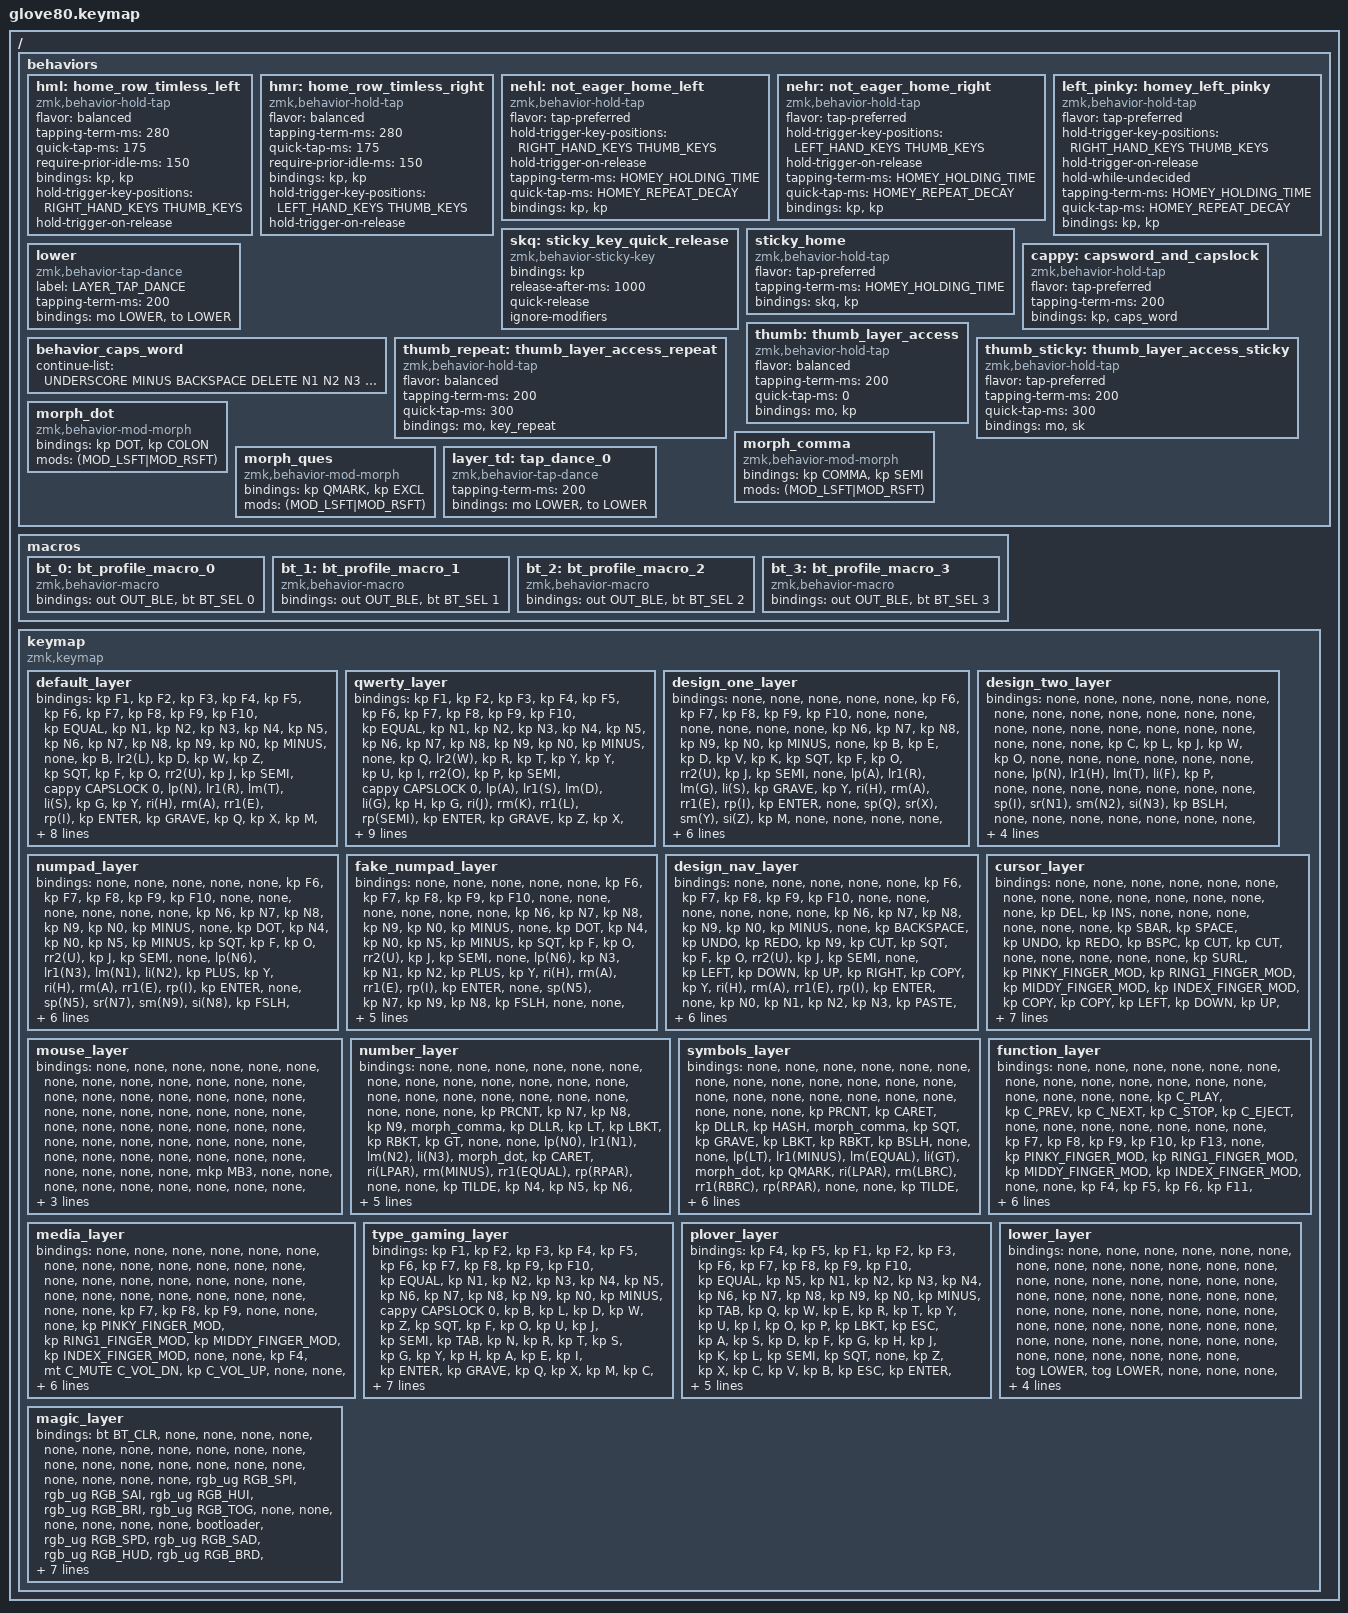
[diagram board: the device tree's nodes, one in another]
/*
 * Copyright (c) 2020 The ZMK Contributors
 *
 * SPDX-License-Identifier: MIT
 */


#include <dt-bindings/zmk/hid_usage.h>
#include <dt-bindings/zmk/hid_usage_pages.h>
#include <dt-bindings/zmk/modifiers.h>

#include <dt-bindings/zmk/mouse.h>
#include <dt-bindings/zmk/keys.h>
#include <dt-bindings/zmk/bt.h>
#include <dt-bindings/zmk/ext_power.h>
#include <dt-bindings/zmk/outputs.h>
#include <dt-bindings/zmk/rgb.h>

#include <behaviors.dtsi>
 
#include "./config.dtsi"
#include "./features/thumbs.dtsi"
#include "./features/shortcuts.dtsi"
#include "./features/combos.dtsi"



/ {
  behaviors {
    #ifndef PINKY_FINGER_MOD
    #define PINKY_FINGER_MOD LGUI
    #endif

    #ifndef RING1_FINGER_MOD
    #define RING1_FINGER_MOD LALT
    #endif

    #ifndef RING2_FINGER_MOD
    #define RING2_FINGER_MOD RALT
    #endif

    #ifndef MIDDY_FINGER_MOD
    #define MIDDY_FINGER_MOD LSFT
    #endif

    #ifndef INDEX_FINGER_MOD
    #define INDEX_FINGER_MOD LCTL
    #endif

    #define LEFT_HAND_KEYS      \
          0  1  2  3  4         \
         10 11 12 13 14 15      \
         22 23 24 25 26 27      \
         34 35 36 37 38 39      \
         46 47 48 49 50 51      \
         64 65 66 67 68

    #define RIGHT_HAND_KEYS     \
                                           5  6  7  8  9 \
                                       16 17 18 19 20 21 \
                                       28 29 30 31 32 33 \
                                       40 41 42 43 44 45 \
                                       58 59 60 61 62 63 \
                                          75 76 77 78 79

    #define THUMB_KEYS          \
                        69 52       57 74                \
                         70 53     56 73                 \
                          71 54   55 72

    // HOMEY_HOLDING_TIME defines how long you need to hold (milliseconds)
    // home row mod keys in order to send their modifiers to the computer
    // (i.e. "register" them) for mod-click mouse usage (e.g. Ctrl-Click).
    #ifndef HOMEY_HOLDING_TIME
    #define HOMEY_HOLDING_TIME 170 // TAPPING_TERM + ALLOW_CROSSOVER_AFTER
    #endif

    // HOMEY_STREAK_DECAY defines how long you need to wait (milliseconds)
    // after typing before you can use home row mods again.  It prevents
    // unintended activation of home row mods when you're actively typing.
    #ifndef HOMEY_STREAK_DECAY
    #define HOMEY_STREAK_DECAY 100
    #endif

    // HOMEY_REPEAT_DECAY defines how much time you have left (milliseconds)
    // after tapping a key to hold it again in order to make it auto-repeat.
    #ifndef HOMEY_REPEAT_DECAY
    #define HOMEY_REPEAT_DECAY 300 // "tap then hold" for key auto-repeat
    #endif

    hml: home_row_timless_left {
      compatible = "zmk,behavior-hold-tap";
      flavor = "balanced";
      tapping-term-ms = <280>;
      quick-tap-ms = <175>;
      require-prior-idle-ms = <150>;
      #binding-cells = <2>;
      bindings = <&kp>, <&kp>;
      hold-trigger-key-positions = <RIGHT_HAND_KEYS THUMB_KEYS>;
      hold-trigger-on-release;
    };

    hmr: home_row_timless_right {
      compatible = "zmk,behavior-hold-tap";
      flavor = "balanced";
      tapping-term-ms = <280>;
      quick-tap-ms = <175>;
      require-prior-idle-ms = <150>;
      #binding-cells = <2>;
      bindings = <&kp>, <&kp>;
      hold-trigger-key-positions = <LEFT_HAND_KEYS THUMB_KEYS>;
      hold-trigger-on-release;
    };

    #define lp(key) hml PINKY_FINGER_MOD key
    #define lr1(key) hml RING1_FINGER_MOD key
    #define lr2(key) hml RING2_FINGER_MOD key
    #define lm(key) hml LSFT key
    #define li(key) hml LCTL key

    #define rp(key) hmr PINKY_FINGER_MOD key
    #define rr1(key) hmr RING1_FINGER_MOD key
    #define rr2(key) hmr RING2_FINGER_MOD key
    #define rm(key) hmr RSFT key
    #define ri(key) hmr RCTL key

    nehl: not_eager_home_left {
      compatible = "zmk,behavior-hold-tap";
      flavor = "tap-preferred";
      hold-trigger-key-positions = <RIGHT_HAND_KEYS THUMB_KEYS>;
      hold-trigger-on-release; // wait for other home row mods 
      tapping-term-ms = <HOMEY_HOLDING_TIME>;
      quick-tap-ms = <HOMEY_REPEAT_DECAY>;
      #binding-cells = <2>;
      bindings = <&kp>, <&kp>;
    };

    nehr: not_eager_home_right {
      compatible = "zmk,behavior-hold-tap";
      flavor = "tap-preferred";
      hold-trigger-key-positions = <LEFT_HAND_KEYS THUMB_KEYS>;
      hold-trigger-on-release; // wait for other home row mods 
      tapping-term-ms = <HOMEY_HOLDING_TIME>;
      quick-tap-ms = <HOMEY_REPEAT_DECAY>;
      #binding-cells = <2>;
      bindings = <&kp>, <&kp>;
    };

    left_pinky: homey_left_pinky {
      compatible = "zmk,behavior-hold-tap";
      flavor = "tap-preferred";
      hold-trigger-key-positions = <RIGHT_HAND_KEYS THUMB_KEYS>;
      hold-trigger-on-release; // wait for other home row mods
      hold-while-undecided;
      tapping-term-ms = <HOMEY_HOLDING_TIME>;
      quick-tap-ms = <HOMEY_REPEAT_DECAY>;
      #binding-cells = <2>;
      bindings = <&kp>, <&kp>;
    };

    skq: sticky_key_quick_release {
        compatible = "zmk,behavior-sticky-key";
        #binding-cells = <1>;
        bindings = <&kp>;
        release-after-ms = <1000>;
        quick-release;
        ignore-modifiers;
      };

    sticky_home: sticky_home {
      compatible = "zmk,behavior-hold-tap";
      flavor = "tap-preferred";
      tapping-term-ms = <HOMEY_HOLDING_TIME>;
      #binding-cells = <2>;
      bindings = <&skq>, <&kp>;
    };

    /* #define lp(key) nehl PINKY_FINGER_MOD key */
    /* #define lr1(key) nehl RING1_FINGER_MOD key */
    /* #define lr2(key) nehl RING2_FINGER_MOD key */
    /* #define lm(key) nehl LSFT key */
    /* #define li(key) nehl LCTL key */
    /**/
    /* #define rp(key) nehr PINKY_FINGER_MOD key */
    /* #define rr1(key) nehr RING1_FINGER_MOD key */
    /* #define rr2(key) nehr RING2_FINGER_MOD key */
    /* #define rm(key) nehr RSFT key */
    /* #define ri(key) nehr RCTL key */

    #define sp(key) sticky_home PINKY_FINGER_MOD key
    #define sr(key) sticky_home RING1_FINGER_MOD key
    #define sm(key) sticky_home RSFT key
    #define si(key) sticky_home RCTL key

    lower: lower {
      compatible = "zmk,behavior-tap-dance";
      label = "LAYER_TAP_DANCE";
      #binding-cells = <0>;
      tapping-term-ms = <200>;
      bindings = <&mo LOWER>, <&to LOWER>;
    };

    #define UNDO LC(Z) 
    #define REDO LC(LS(Z)) 

    #define SBAR LC(K) 
    #define SURL LC(L) 

    #define CUT LC(X) 
    #define COPY LC(C) 
    #define PASTE LC(V) 

    #define FIND LC(F) 
    #define FPRE LC(LS(G)) 
    #define FNEX LC(G) 

    #define SALL LC(A) 


    cappy: capsword_and_capslock {
      compatible = "zmk,behavior-hold-tap";
      flavor = "tap-preferred";
      tapping-term-ms = <200>;
      #binding-cells = <2>;
      bindings = <&kp>, <&caps_word>;
    };


    behavior_caps_word {
      continue-list = <
        UNDERSCORE MINUS
        BACKSPACE DELETE
        N1 N2 N3 N4 N5 N6 N7 N8 N9 N0
      >;
    };

    thumb: thumb_layer_access {
      compatible = "zmk,behavior-hold-tap";
      flavor = "balanced";
      tapping-term-ms = <200>;
      quick-tap-ms = <0>; // enable repeat
      #binding-cells = <2>;
      bindings = <&mo>, <&kp>;
    };

    thumb_repeat: thumb_layer_access_repeat {
      compatible = "zmk,behavior-hold-tap";
      flavor = "balanced";
      tapping-term-ms = <200>;
      quick-tap-ms = <300>; // enable repeat
      #binding-cells = <2>;
      bindings = <&mo>, <&key_repeat>;
    };

    thumb_sticky: thumb_layer_access_sticky {
      compatible = "zmk,behavior-hold-tap";
      flavor = "tap-preferred";
      tapping-term-ms = <200>;
      quick-tap-ms = <300>; // enable repeat
      #binding-cells = <2>;
      bindings = <&mo>, <&sk>;
    };
    
    morph_dot: morph_dot {
      compatible = "zmk,behavior-mod-morph";
      #binding-cells = <0>;
      bindings = <&kp DOT>, <&kp COLON>;
      mods = <(MOD_LSFT|MOD_RSFT)>;
    };

    morph_comma: morph_comma {
      compatible = "zmk,behavior-mod-morph";
      #binding-cells = <0>;
      bindings = <&kp COMMA>, <&kp SEMI>;
      mods = <(MOD_LSFT|MOD_RSFT)>;
    };

    morph_ques: morph_ques {
      compatible = "zmk,behavior-mod-morph";
      #binding-cells = <0>;
      bindings = <&kp QMARK>, <&kp EXCL>;
      mods = <(MOD_LSFT|MOD_RSFT)>;
    };

    // For the "layer" key, it'd nice to be able to use it as either a shift or a toggle.
    // Configure it as a tap dance, so the first tap (or hold) is a &mo and the second tap is a &to
    layer_td: tap_dance_0 {
        compatible = "zmk,behavior-tap-dance";
        #binding-cells = <0>;
        tapping-term-ms = <200>;
        bindings = <&mo LOWER>, <&to LOWER>;
    };
  };

  macros {
      bt_0: bt_profile_macro_0 {
          compatible = "zmk,behavior-macro";
          #binding-cells = <0>;

          bindings
              = <&out OUT_BLE>,
                <&bt BT_SEL 0>;
      };

      bt_1: bt_profile_macro_1 {
          compatible = "zmk,behavior-macro";
          #binding-cells = <0>;
          bindings
              = <&out OUT_BLE>,
                <&bt BT_SEL 1>;
      };

      bt_2: bt_profile_macro_2 {
          compatible = "zmk,behavior-macro";
          #binding-cells = <0>;
          bindings
              = <&out OUT_BLE>,
                <&bt BT_SEL 2>;
      };

      bt_3: bt_profile_macro_3 {
          compatible = "zmk,behavior-macro";
          #binding-cells = <0>;
          bindings
              = <&out OUT_BLE>,
                <&bt BT_SEL 3>;
      };
  };

  keymap {
    compatible = "zmk,keymap";

    default_layer {
        // ---------------------------------------------------------------------------------------------------------------------------------
        // |  F1   |  F2 |  F3 |  F4  |  F5  |                                                               |  F6   |  F7   |  F8  |   F9  |  F10 |
        // |  =    |  1  |  2  |  3   |  4   |  5   |                                                 |  6   |   7   |   8   |  9   |   0   |   -  |
        // |  TAB  |  Q  |  W  |  E   |  R   |  T   |                                                 |  Y   |   U   |   I   |  O   |   P   |   \  |
        // |  ESC  |  A  |  S  |  D   |  F   |  G   |                                                 |  H   |   J   |   K   |  L   |   ;   |   '  |
        // |   `   |  Z  |  X  |  C   |  V   |  B   | LSHFT | LCTRL | LOWER | | LGUI  | RCTRL | RSHFT |  N   |   M   |   ,   |  .   |   /   | PGUP |
        // | MAGIC | HOME| END | LEFT | RIGHT|      | BSPC  | DEL   | LALT  | | RALT  | RET   | SPACE |      |  UP   | DOWN  |  [   |   ]   | PGDN |

        bindings = <
        &kp F1      &kp F2             &kp F3          &kp F4          &kp F5                                                                                                                           &kp F6           &kp F7           &kp F8          &kp F9      &kp F10
        &kp EQUAL   &kp N1             &kp N2          &kp N3          &kp N4          &kp N5                                                                                                 &kp N6    &kp N7           &kp N8           &kp N9          &kp N0      &kp MINUS
        &none     &kp B              &lr2(L)   &kp D           &kp W           &kp Z                                                                                                  &kp SQT   &kp F            &kp O            &rr2(U)  &kp J       &kp SEMI
        &cappy CAPSLOCK 0     &lp(N)      &lr1(R)   &lm(T)   &li(S)   &kp G                                                                                                  &kp Y     &ri(H)   &rm(A)   &rr1(E)  &rp(I)       &kp ENTER
        &kp GRAVE   &kp Q    &kp X     &kp M           &kp C           &kp V           &thumb FUNCTION MINUS    &none   &none   &none    &none                   &skq LSHIFT   &kp K     &kp P            &morph_dot         &morph_comma        &kp FSLH   &kp PG_UP
        &mo MAGIC   &kp HOME &kp END   &kp DOWN          &kp UP        &thumb NUMBER SPACE   &thumb CURSOR UNDER    &lower   &lower   &thumb MEDIA ENTER   &thumb SYMBOLS BACKSPACE       &kp LEFT           &kp RIGHT         &kp LBKT         &kp RBKT   &kp PG_DN
        >;
    };

    qwerty_layer {
        // ---------------------------------------------------------------------------------------------------------------------------------
        // |  F1   |  F2 |  F3 |  F4  |  F5  |                                                               |  F6   |  F7   |  F8  |   F9  |  F10 |
        // |  =    |  1  |  2  |  3   |  4   |  5   |                                                 |  6   |   7   |   8   |  9   |   0   |   -  |
        // |  TAB  |  Q  |  W  |  E   |  R   |  T   |                                                 |  Y   |   U   |   I   |  O   |   P   |   \  |
        // |  ESC  |  A  |  S  |  D   |  F   |  G   |                                                 |  H   |   J   |   K   |  L   |   ;   |   '  |
        // |   `   |  Z  |  X  |  C   |  V   |  B   | LSHFT | LCTRL | LOWER | | LGUI  | RCTRL | RSHFT |  N   |   M   |   ,   |  .   |   /   | PGUP |
        // | MAGIC | HOME| END | LEFT | RIGHT|      | BSPC  | DEL   | LALT  | | RALT  | RET   | SPACE |      |  UP   | DOWN  |  [   |   ]   | PGDN |

        bindings = <
        &kp F1      &kp F2             &kp F3          &kp F4          &kp F5                                                                                                                           &kp F6           &kp F7           &kp F8          &kp F9      &kp F10
        &kp EQUAL   &kp N1             &kp N2          &kp N3          &kp N4          &kp N5                                                                                                 &kp N6    &kp N7           &kp N8           &kp N9          &kp N0      &kp MINUS
        &none     &kp Q              &lr2(W)   &kp R           &kp T           &kp Y                                                                                                  &kp Y   &kp U            &kp I            &rr2(O)  &kp P       &kp SEMI
        &cappy CAPSLOCK 0     &lp(A)      &lr1(S)   &lm(D)   &li(G)   &kp H                                                                                                  &kp G     &ri(J)   &rm(K)   &rr1(L)  &rp(SEMI)       &kp ENTER
        &kp GRAVE   &kp Z    &kp X     &kp C           &kp V           &kp B           &thumb FUNCTION MINUS    &none   &tog PLOVER   &tog QWERTY    &kp LEFT                   &kp ESC   &kp N     &kp P            &morph_comma         &morph_dot        &kp FSLH   &kp PG_UP
        &mo MAGIC   &kp HOME &kp END   &kp DOWN          &kp UP        &thumb NUMBER SPACE   &thumb CURSOR UNDER    &lower   &lower   &thumb MEDIA ENTER   &thumb SYMBOLS BACKSPACE       &kp LEFT           &kp RIGHT         &kp LBKT         &kp RBKT   &kp PG_DN
        >;
    };

    design_one_layer {
        bindings = <
        &none   &none    &none     &none   &none                                                                                                                               &kp F6           &kp F7           &kp F8          &kp F9      &kp F10
        &none   &none    &none     &none   &none    &none                                                                                                     &kp N6    &kp N7           &kp N8           &kp N9          &kp N0      &kp MINUS
        &none   &kp B    &kp E     &kp D   &kp V    &kp K                                                                                                      &kp SQT   &kp F            &kp O            &rr2(U)  &kp J       &kp SEMI
        &none   &lp(A)   &lr1(R)   &lm(G)  &li(S)   &kp GRAVE                                                                                                  &kp Y     &ri(H)   &rm(A)   &rr1(E)  &rp(I)       &kp ENTER
        &none   &sp(Q)   &sr(X)    &sm(Y)  &si(Z)   &kp M       &none                &none            &none   &none   &none   &kp ESC   &kp K     &kp P            &kp DOT         &kp COMMA        &kp FSLH   &kp PG_UP
        &none   &none    &none     &none   &none                &dln NUMPAD DESTWO   &dln DNAV DESTWO   &none   &none   &none   &thumb_repeat SYMBOLS 0       &kp LEFT           &kp RIGHT         &kp LBKT         &kp RBKT   &kp PG_DN
        >;
    };

     design_two_layer {
         bindings = <
         &none   &none    &none     &none    &none                                                                                           &none    &none  &none   &none    &none
         &none   &none    &none     &none    &none     &none                                                                         &none   &none    &none  &none   &none    &none
         &none   &kp C    &kp L     &kp J    &kp W     &kp O                                                                         &none   &none    &none  &none   &none    &none
         &none   &lp(N)   &lr1(H)   &lm(T)   &li(F)    &kp P                                                                         &none   &none    &none  &none   &none    &none
         &none   &sp(I)   &sr(N1)   &sm(N2)  &si(N3)   &kp BSLH   &none                &none         &none   &none   &none   &none   &none   &none    &none  &none   &none    &none
         &none   &none    &none     &none    &none                &dln NUMPAD DESTWO   &thumb DNAV U   &none   &none   &none   &none           &none    &none  &none   &none    &none
         >;
     };

    numpad_layer {
        bindings = <
        &none   &none      &none    &none    &none                                                                                                                          &kp F6           &kp F7           &kp F8          &kp F9      &kp F10
        &none   &none      &none    &none    &none    &none                                                                                                  &kp N6    &kp N7           &kp N8           &kp N9          &kp N0      &kp MINUS
        &none   &kp DOT    &kp N4   &kp N0   &kp N5   &kp MINUS                                                                                           &kp SQT   &kp F            &kp O            &rr2(U)  &kp J       &kp SEMI
        &none   &lp(N6)    &lr1(N3)   &lm(N1)   &li(N2)   &kp PLUS                                                                                            &kp Y     &ri(H)   &rm(A)   &rr1(E)  &rp(I)       &kp ENTER
        &none   &sp(N5)    &sr(N7)   &sm(N9)   &si(N8)   &kp FSLH    &none    &none    &none   &none   &none   &kp ESC   &kp K     &kp P            &kp DOT         &kp COMMA        &kp FSLH   &kp PG_UP
        &none   &none      &none    &none    &none                &trans   &trans   &none   &none   &none   &thumb_repeat SYMBOLS 0       &kp LEFT           &kp RIGHT         &kp LBKT         &kp RBKT   &kp PG_DN
        >;
    };

    fake_numpad_layer {
        bindings = <
        &none   &none      &none    &none    &none                                                                                                                           &kp F6           &kp F7           &kp F8          &kp F9      &kp F10
        &none   &none      &none    &none    &none    &none                                                                                                  &kp N6    &kp N7           &kp N8           &kp N9          &kp N0      &kp MINUS
        &none   &kp DOT    &kp N4   &kp N0   &kp N5   &kp MINUS                                                                                           &kp SQT   &kp F            &kp O            &rr2(U)  &kp J       &kp SEMI
        &none   &lp(N6)    &kp N3   &kp N1   &kp N2   &kp PLUS                                                                                            &kp Y     &ri(H)   &rm(A)   &rr1(E)  &rp(I)       &kp ENTER
        &none   &sp(N5)    &kp N7   &kp N9   &kp N8   &kp FSLH    &none    &none    &none   &none   &none   &kp ESC   &kp K     &kp P            &kp DOT         &kp COMMA        &kp FSLH   &kp PG_UP
        &none   &none      &none    &none    &none                &trans   &trans   &none   &none   &none   &thumb_repeat SYMBOLS 0       &kp LEFT           &kp RIGHT         &kp LBKT         &kp RBKT   &kp PG_DN
        >;
    };
    
    design_nav_layer {
        bindings = <
        &none   &none           &none        &none        &none                                                                                                                              &kp F6           &kp F7           &kp F8          &kp F9      &kp F10
        &none   &none           &none        &none        &none       &none                                                                                                  &kp N6    &kp N7           &kp N8           &kp N9          &kp N0      &kp MINUS
        &none   &kp BACKSPACE   &kp UNDO   &kp REDO   &kp N9      &kp CUT                                                                                           &kp SQT   &kp F            &kp O            &rr2(U)  &kp J       &kp SEMI
        &none   &kp LEFT        &kp DOWN     &kp UP       &kp RIGHT   &kp COPY                                                                                            &kp Y     &ri(H)   &rm(A)   &rr1(E)  &rp(I)       &kp ENTER
        &none   &kp N0          &kp N1       &kp N2       &kp N3      &kp PASTE    &none    &none    &none   &none   &none   &kp ESC   &kp K     &kp P            &kp DOT         &kp COMMA        &kp FSLH   &kp PG_UP
        &none   &none           &none        &none        &none                   &trans   &trans   &none   &none   &none   &thumb_repeat SYMBOLS 0       &kp LEFT           &kp RIGHT         &kp LBKT         &kp RBKT   &kp PG_DN
        >;
    };

    cursor_layer {
        // ---------------------------------------------------------------------------------------------------------------------------------
        // |  F1   |  F2 |  F3 |  F4  |  F5  |                                                               |  F6   |  F7   |  F8  |   F9  |  F10 |
        // |  =    |  1  |  2  |  3   |  4   |  5   |                                                 |  6   |   7   |   8   |  9   |   0   |   -  |
        // |  TAB  |  Q  |  W  |  E   |  R   |  T   |                                                 |  Y   |   U   |   I   |  O   |   P   |   \  |
        // |  ESC  |  A  |  S  |  D   |  F   |  G   |                                                 |  H   |   J   |   K   |  L   |   ;   |   '  |
        // |   `   |  Z  |  X  |  C   |  V   |  B   | LSHFT | LCTRL | LOWER | | LGUI  | RCTRL | RSHFT |  N   |   M   |   ,   |  .   |   /   | PGUP |
        // | MAGIC | HOME| END | LEFT | RIGHT|      | BSPC  | DEL   | LALT  | | RALT  | RET   | SPACE |      |  UP   | DOWN  |  [   |   ]   | PGDN |

        bindings = <
        &none       &none                  &none                  &none                  &none                                                                                                             &none      &none       &none       &none      &none
        &none       &none                  &none                  &none                  &kp DEL                &kp INS                                                                        &none       &none      &none       &none       &none      &none
        &kp SBAR    &kp SPACE              &kp UNDO               &kp REDO               &kp BSPC               &kp CUT                                                                        &kp CUT     &none      &none       &none       &none      &none
        &kp SURL    &kp PINKY_FINGER_MOD   &kp RING1_FINGER_MOD   &kp MIDDY_FINGER_MOD   &kp INDEX_FINGER_MOD   &kp COPY                                                                       &kp COPY    &kp LEFT   &kp DOWN    &kp UP      &kp RIGHT  &none
        &kp LC(T)   &kp LC(F)              &none                  &none                  &kp SALL               &kp PASTE   &kp TAB   &none   &tog CURSOR   &tog CURSOR    &none   &none       &kp PASTE   &kp HOME   &kp PG_DN   &kp PG_UP   &kp END    &none
        &kp LC(W)   &kp FPRE               &none                  &none                  &kp FNEX                           &none     &none   &none         &none          &none   &kp SPACE               &none      &none       &none       &none      &none
        >;
    };

    mouse_layer {
        // ---------------------------------------------------------------------------------------------------------------------------------
        // |  F1   |  F2 |  F3 |  F4  |  F5  |                                                               |  F6   |  F7   |  F8  |   F9  |  F10 |
        // |  =    |  1  |  2  |  3   |  4   |  5   |                                                 |  6   |   7   |   8   |  9   |   0   |   -  |
        // |  TAB  |  Q  |  W  |  E   |  R   |  T   |                                                 |  Y   |   U   |   I   |  O   |   P   |   \  |
        // |  ESC  |  A  |  S  |  D   |  F   |  G   |                                                 |  H   |   J   |   K   |  L   |   ;   |   '  |
        // |   `   |  Z  |  X  |  C   |  V   |  B   | LSHFT | LCTRL | LOWER | | LGUI  | RCTRL | RSHFT |  N   |   M   |   ,   |  .   |   /   | PGUP |
        // | MAGIC | HOME| END | LEFT | RIGHT|      | BSPC  | DEL   | LALT  | | RALT  | RET   | SPACE |      |  UP   | DOWN  |  [   |   ]   | PGDN |

        bindings = <
        &none   &none   &none   &none   &none                                                                         &none   &none   &none   &none   &none
        &none   &none   &none   &none   &none   &none                                                         &none   &none   &none   &none   &none   &none
        &none   &none   &none   &none   &none   &none                                                         &none   &none   &none   &none   &none   &none
        &none   &none   &none   &none   &none   &none                                                         &none   &none   &none   &none   &none   &none
        &none   &none   &none   &none   &none   &none   &mkp MB3   &none      &none   &none   &none   &none   &none   &none   &none   &none   &none   &none
        &none   &none   &none   &none   &none           &mkp MB1   &mkp MB2   &none   &none   &none   &none           &none   &none   &none   &none   &none
        >;
    };

    number_layer {
        // ---------------------------------------------------------------------------------------------------------------------------------
        // |  F1   |  F2 |  F3 |  F4  |  F5  |                                                               |  F6   |  F7   |  F8  |   F9  |  F10 |
        // |  =    |  1  |  2  |  3   |  4   |  5   |                                                 |  6   |   7   |   8   |  9   |   0   |   -  |
        // |  TAB  |  Q  |  W  |  E   |  R   |  T   |                                                 |  Y   |   U   |   I   |  O   |   P   |   \  |
        // |  ESC  |  A  |  S  |  D   |  F   |  G   |                                                 |  H   |   J   |   K   |  L   |   ;   |   '  |
        // |   `   |  Z  |  X  |  C   |  V   |  B   | LSHFT | LCTRL | LOWER | | LGUI  | RCTRL | RSHFT |  N   |   M   |   ,   |  .   |   /   | PGUP |
        // | MAGIC | HOME| END | LEFT | RIGHT|      | BSPC  | DEL   | LALT  | | RALT  | RET   | SPACE |      |  UP   | DOWN  |  [   |   ]   | PGDN |

        bindings = <
        &none   &none       &none      &none     &none                                                                        &none       &none       &none        &none         &none
        &none   &none       &none      &none     &none     &none                                                              &none       &none       &none        &none         &none       &none
        &none   &kp PRCNT   &kp N7     &kp N8    &kp N9    &morph_comma                                                       &kp DLLR    &kp LT      &kp LBKT     &kp RBKT      &kp GT      &none
        &none   &lp(N0)     &lr1(N1)   &lm(N2)   &li(N3)   &morph_dot                                                         &kp CARET   &ri(LPAR)   &rm(MINUS)   &rr1(EQUAL)   &rp(RPAR)   &none
        &none   &kp TILDE   &kp N4     &kp N5    &kp N6    &kp AT       &none   &none   &none         &none   &none   &none   &kp CARET   &kp PLUS    &kp UNDER    &kp ASTRK     &kp FSLH    &none
        &none   &none       &none      &none     &none                  &none   &none   &tog NUMBER   &none   &kp BACKSPACE   &kp SPACE   &trans      &trans      &trans       &trans        &none
        >;
    };

    symbols_layer {
        // ---------------------------------------------------------------------------------------------------------------------------------
        // |  F1   |  F2 |  F3 |  F4  |  F5  |                                                               |  F6   |  F7   |  F8  |   F9  |  F10 |
        // |  =    |  1  |  2  |  3   |  4   |  5   |                                                 |  6   |   7   |   8   |  9   |   0   |   -  |
        // |  TAB  |  Q  |  W  |  E   |  R   |  T   |                                                 |  Y   |   U   |   I   |  O   |   P   |   \  |
        // |  ESC  |  A  |  S  |  D   |  F   |  G   |                                                 |  H   |   J   |   K   |  L   |   ;   |   '  |
        // |   `   |  Z  |  X  |  C   |  V   |  B   | LSHFT | LCTRL | LOWER | | LGUI  | RCTRL | RSHFT |  N   |   M   |   ,   |  .   |   /   | PGUP |
        // | MAGIC | HOME| END | LEFT | RIGHT|      | BSPC  | DEL   | LALT  | | RALT  | RET   | SPACE |      |  UP   | DOWN  |  [   |   ]   | PGDN |

        bindings = <
        &none   &none       &none         &none        &none                                                                         &none       &none       &none       &none        &none
        &none   &none       &none         &none        &none      &none                                                              &none       &none       &none       &none        &none       &none
        &none   &kp PRCNT   &kp CARET     &kp DLLR     &kp HASH   &morph_comma                                                       &kp SQT     &kp GRAVE   &kp LBKT    &kp RBKT     &kp BSLH    &none
        &none   &lp(LT)     &lr1(MINUS)   &lm(EQUAL)   &li(GT)    &morph_dot                                                         &kp QMARK   &ri(LPAR)   &rm(LBRC)   &rr1(RBRC)   &rp(RPAR)   &none
        &none   &kp TILDE   &kp UNDER     &kp PIPE     &kp AMPS   &kp AT       &none       &none   &none   &none   &none   &none   &kp EXCL    &kp PLUS    &kp MINUS   &kp ASTRK    &kp FSLH    &none
        &none   &none       &none         &none        &none                   &kp SPACE   &kp BACKSPACE   &tog NUMBER   &none   &none   &none   &trans      &trans      &trans      &trans       &none
        >;
    };


    function_layer {
        // ---------------------------------------------------------------------------------------------------------------------------------
        // |  F1   |  F2 |  F3 |  F4  |  F5  |                                                               |  F6   |  F7   |  F8  |   F9  |  F10 |
        // |  =    |  1  |  2  |  3   |  4   |  5   |                                                 |  6   |   7   |   8   |  9   |   0   |   -  |
        // |  TAB  |  Q  |  W  |  E   |  R   |  T   |                                                 |  Y   |   U   |   I   |  O   |   P   |   \  |
        // |  ESC  |  A  |  S  |  D   |  F   |  G   |                                                 |  H   |   J   |   K   |  L   |   ;   |   '  |
        // |   `   |  Z  |  X  |  C   |  V   |  B   | LSHFT | LCTRL | LOWER | | LGUI  | RCTRL | RSHFT |  N   |   M   |   ,   |  .   |   /   | PGUP |
        // | MAGIC | HOME| END | LEFT | RIGHT|      | BSPC  | DEL   | LALT  | | RALT  | RET   | SPACE |      |  UP   | DOWN  |  [   |   ]   | PGDN |

        bindings = <
        &none   &none   &none   &none   &none                                                                                                           &none        &none   &none   &none   &none
        &none   &none   &none   &none   &none   &none                                                                                           &none   &kp C_PLAY   &kp C_PREV   &kp C_NEXT   &kp C_STOP   &kp C_EJECT
        &none   &none   &none   &none   &none   &none                                                                                           &none   &kp F7       &kp  F8   &kp F9   &kp F10   &kp F13
        &none   &kp PINKY_FINGER_MOD   &kp RING1_FINGER_MOD   &kp MIDDY_FINGER_MOD   &kp INDEX_FINGER_MOD   &none                                                                                           &none   &kp F4       &kp  F5   &kp F6   &kp F11   &kp F14
        &none   &none   &none   &none   &none   &none   &none         &none         &tog FUNCTION   &none         &none          &kp C_PP       &none   &kp F1       &kp  F4   &kp F3   &kp F12   &kp F15
        &none   &none   &none   &none   &none           &none         &none         &none           &kp C_MUTE    &kp C_VOL_DN   &kp C_VOL_UP           &none        &none   &none   &none   &none
        >;
    };

    media_layer {
        // ---------------------------------------------------------------------------------------------------------------------------------
        // |  F1   |  F2 |  F3 |  F4  |  F5  |                                                               |  F6   |  F7   |  F8  |   F9  |  F10 |
        // |  =    |  1  |  2  |  3   |  4   |  5   |                                                 |  6   |   7   |   8   |  9   |   0   |   -  |
        // |  TAB  |  Q  |  W  |  E   |  R   |  T   |                                                 |  Y   |   U   |   I   |  O   |   P   |   \  |
        // |  ESC  |  A  |  S  |  D   |  F   |  G   |                                                 |  H   |   J   |   K   |  L   |   ;   |   '  |
        // |   `   |  Z  |  X  |  C   |  V   |  B   | LSHFT | LCTRL | LOWER | | LGUI  | RCTRL | RSHFT |  N   |   M   |   ,   |  .   |   /   | PGUP |
        // | MAGIC | HOME| END | LEFT | RIGHT|      | BSPC  | DEL   | LALT  | | RALT  | RET   | SPACE |      |  UP   | DOWN  |  [   |   ]   | PGDN |

        bindings = <
        &none   &none   &none   &none   &none                                                                               &none      &none                 &none          &none   &none
        &none   &none   &none   &none   &none   &none                                                               &none   &none      &none                 &none          &none   &none
        &none   &none   &none   &none   &none   &none                                                               &none   &kp F7     &kp F8                &kp F9         &none   &none
        &none   &kp PINKY_FINGER_MOD   &kp RING1_FINGER_MOD   &kp MIDDY_FINGER_MOD   &kp INDEX_FINGER_MOD   &none   &none   &kp F4     &mt C_MUTE C_VOL_DN   &kp C_VOL_UP   &none   &none
        &none   &none   &none   &none   &none   &none   &none         &none         &none   &none   &none   &none   &none   &kp C_PP   &kp C_PREV            &kp C_NEXT     &none   &none
        &none   &none   &none   &none   &none           &none         &none         &none   &none   &none   &none           &none      &none                 &none          &none   &none
        >;
    };

    type_gaming_layer {
        // ---------------------------------------------------------------------------------------------------------------------------------
        // |  F1   |  F2 |  F3 |  F4  |  F5  |                                                               |  F6   |  F7   |  F8  |   F9  |  F10 |
        // |  =    |  1  |  2  |  3   |  4   |  5   |                                                 |  6   |   7   |   8   |  9   |   0   |   -  |
        // |  TAB  |  Q  |  W  |  E   |  R   |  T   |                                                 |  Y   |   U   |   I   |  O   |   P   |   \  |
        // |  ESC  |  A  |  S  |  D   |  F   |  G   |                                                 |  H   |   J   |   K   |  L   |   ;   |   '  |
        // |   `   |  Z  |  X  |  C   |  V   |  B   | LSHFT | LCTRL | LOWER | | LGUI  | RCTRL | RSHFT |  N   |   M   |   ,   |  .   |   /   | PGUP |
        // | MAGIC | HOME| END | LEFT | RIGHT|      | BSPC  | DEL   | LALT  | | RALT  | RET   | SPACE |      |  UP   | DOWN  |  [   |   ]   | PGDN |

        bindings = <
        &kp F1             &kp F2  &kp F3  &kp F4  &kp F5                                                                                                                &kp F6     &kp F7      &kp F8        &kp F9       &kp F10
        &kp EQUAL          &kp N1  &kp N2  &kp N3  &kp N4  &kp N5                                                                                             &kp N6     &kp N7     &kp N8      &kp N9        &kp N0       &kp MINUS
        &cappy CAPSLOCK 0  &kp B   &kp L   &kp D   &kp W   &kp Z                                                                                              &kp SQT    &kp F      &kp O       &kp U         &kp J        &kp SEMI
        &kp TAB            &kp N   &kp R   &kp T   &kp S   &kp G                                                                                              &kp Y      &kp H      &kp A       &kp E         &kp I        &kp ENTER
        &kp GRAVE          &kp Q   &kp X   &kp M   &kp C   &kp V   &thumb FUNCTION DEL  &none          &tog TYPEG  &none  &none  &kp ESC                      &kp K      &kp P      &morph_dot  &morph_comma  &morph_ques  &kp PG_UP
        &mo MAGIC          &none   &none   &none   &kp UP          &thumb NUMBER SPACE  &kp BACKSPACE  &none       &none  &none  &thumb_sticky SYMBOLS LSHFT             &kp LEFT   &kp RIGHT   &kp LBKT      &kp RBKT     &kp PG_DN
        >;
    };

    plover_layer {
        // ---------------------------------------------------------------------------------------------------------------------------------
        // |  F1   |  F2 |  F3 |  F4  |  F5  |                                                               |  F6   |  F7   |  F8  |   F9  |  F10 |
        // |  =    |  1  |  2  |  3   |  4   |  5   |                                                 |  6   |   7   |   8   |  9   |   0   |   -  |
        // |  TAB  |  Q  |  W  |  E   |  R   |  T   |                                                 |  Y   |   U   |   I   |  O   |   P   |   \  |
        // |  ESC  |  A  |  S  |  D   |  F   |  G   |                                                 |  H   |   J   |   K   |  L   |   ;   |   '  |
        // |   `   |  Z  |  X  |  C   |  V   |  B   | LSHFT | LCTRL | LOWER | | LGUI  | RCTRL | RSHFT |  N   |   M   |   ,   |  .   |   /   | PGUP |
        // | MAGIC | HOME| END | LEFT | RIGHT|      | BSPC  | DEL   | LALT  | | RALT  | RET   | SPACE |      |  UP   | DOWN  |  [   |   ]   | PGDN |

        bindings = <
        &kp F4         &kp F5   &kp F1   &kp F2   &kp F3                                                                                          &kp F6     &kp F7      &kp F8     &kp F9     &kp F10
        &kp EQUAL      &kp N5   &kp N1   &kp N2   &kp N3      &kp N4                                                                     &kp N6   &kp N7     &kp N8      &kp N9     &kp N0     &kp MINUS
        &kp TAB        &kp Q    &kp W    &kp E    &kp R       &kp T                                                                      &kp Y    &kp U      &kp I       &kp O      &kp P      &kp LBKT    
        &kp ESC        &kp A    &kp S    &kp D    &kp F       &kp G                                                                      &kp H    &kp J      &kp K       &kp L      &kp SEMI   &kp SQT
        &none          &kp Z    &kp X    &kp C    &kp V       &kp B   &kp ESC   &kp ENTER   &tog QWERTY  &tog PLOVER  &kp RCTRL &kp RSHFT   &kp N    &kp M      &kp COMMA   &kp DOT    &kp FSLH   &kp FSLH
        &mo MAGIC      &kp B    &kp N    &kp M    &kp V               &kp C     &kp V       &kp N0     &kp N1     &kp N     &kp M       &kp UP   &kp DOWN   &kp LBKT    &kp RBKT   &kp PG_DN
        >;
    };

    lower_layer {
        // ---------------------------------------------------------------------------------------------------------------------------------
        // |  F1   |  F2 |  F3 |  F4  |  F5  |                                                               |  F6   |  F7   |  F8  |   F9  |  F10 |
        // |  =    |  1  |  2  |  3   |  4   |  5   |                                                 |  6   |   7   |   8   |  9   |   0   |   -  |
        // |  TAB  |  Q  |  W  |  E   |  R   |  T   |                                                 |  Y   |   U   |   I   |  O   |   P   |   \  |
        // |  ESC  |  A  |  S  |  D   |  F   |  G   |                                                 |  H   |   J   |   K   |  L   |   ;   |   '  |
        // |   `   |  Z  |  X  |  C   |  V   |  B   | LSHFT | LCTRL | LOWER | | LGUI  | RCTRL | RSHFT |  N   |   M   |   ,   |  .   |   /   | PGUP |
        // | MAGIC | HOME| END | LEFT | RIGHT|      | BSPC  | DEL   | LALT  | | RALT  | RET   | SPACE |      |  UP   | DOWN  |  [   |   ]   | PGDN |

        bindings = <
        &none   &none   &none   &none   &none                                                                                                  &none   &none   &none   &none   &none
        &none   &none   &none   &none   &none   &none                                                                                  &none   &none   &none   &none   &none   &none
        &none   &none   &none   &none   &none   &none                                                                                  &none   &none   &none   &none   &none   &none
        &none   &none   &none   &none   &none   &none                                                                                  &none   &none   &none   &none   &none   &none
        &none   &none   &none   &none   &none   &none   &none         &none         &tog LOWER   &tog LOWER    &none   &none           &none   &none   &none   &none   &none   &none
        &none   &none   &none   &none   &none           &tog CURSOR   &tog NUMBER   &none        &none         &none   &tog SYMBOLS            &none   &none   &none   &none   &none
        >;
    };

    magic_layer {
        bindings = <
        &bt BT_CLR        &none               &none           &none           &none                                                                                                           &none      &none      &none      &none      &none
        &none             &none               &none           &none           &none           &none                                                                                &none      &none      &none      &none      &none      &none
        &none             &rgb_ug RGB_SPI     &rgb_ug RGB_SAI &rgb_ug RGB_HUI &rgb_ug RGB_BRI &rgb_ug RGB_TOG                                                                      &none      &none      &none      &none      &none      &none
        &bootloader       &rgb_ug RGB_SPD     &rgb_ug RGB_SAD &rgb_ug RGB_HUD &rgb_ug RGB_BRD &rgb_ug RGB_EFF                                                                      &none      &none      &none      &none      &none      &bootloader
        &sys_reset        &none               &none           &none           &none           &none           &bt_2     &bt_3     &none            &none     &none     &none       &none      &none      &none      &none      &none      &sys_reset
        &none             &none               &none           &none           &none                           &bt_0     &bt_1     &out OUT_USB     &none     &none     &none                  &none      &none      &none      &none      &none
        >;
    };
  };
};
